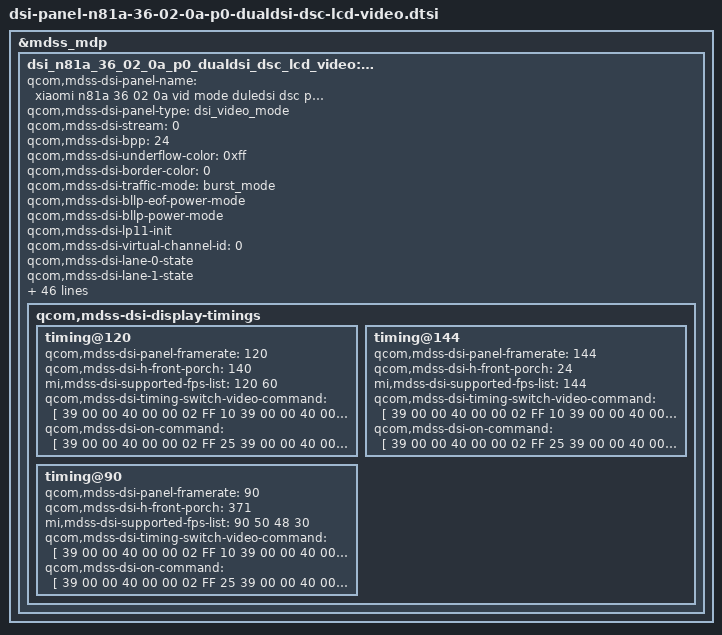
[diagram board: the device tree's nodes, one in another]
/* Copyright (c) 2015, The Linux Foundation. All rights reserved.
 *
 * This program is free software; you can redistribute it and/or modify
 * it under the terms of the GNU General Public License version 2 and
 * only version 2 as published by the Free Software Foundation.
 *
 * This program is distributed in the hope that it will be useful,
 * but WITHOUT ANY WARRANTY; without even the implied warranty of
 * MERCHANTABILITY or FITNESS FOR A PARTICULAR PURPOSE.  See the
 * GNU General Public License for more details.
 */

/*---------------------------------------------------------------------------
 * This file is autogenerated file using gcdb parser. Please do not edit it.
 * Update input XML file to add a new entry or update variable in this file
 * VERSION = "1.0"
 *---------------------------------------------------------------------------*/
&mdss_mdp {
    dsi_n81a_36_02_0a_p0_dualdsi_dsc_lcd_video: qcom,mdss_dsi_n81a_36_02_0a_p0_duledsi_dsc_vid {
        qcom,mdss-dsi-panel-name = "xiaomi n81a 36 02 0a vid mode duledsi dsc panel";
        qcom,mdss-dsi-panel-type = "dsi_video_mode";

        qcom,mdss-dsi-stream = <0>;
        qcom,mdss-dsi-bpp = <24>;
        qcom,mdss-dsi-underflow-color = <0xff>;
        qcom,mdss-dsi-border-color = <0>;
        qcom,mdss-dsi-traffic-mode = "burst_mode";
        qcom,mdss-dsi-bllp-eof-power-mode;
        qcom,mdss-dsi-bllp-power-mode;
        qcom,mdss-dsi-lp11-init;
        qcom,mdss-dsi-virtual-channel-id = <0>;
        qcom,mdss-dsi-lane-0-state;
        qcom,mdss-dsi-lane-1-state;
        qcom,mdss-dsi-lane-2-state;
        qcom,mdss-dsi-lane-3-state;
        qcom,mdss-dsi-dma-trigger = "trigger_sw";
        qcom,mdss-dsi-mdp-trigger = "none";
        qcom,mdss-dsi-reset-sequence = <0 10>, <1 3>, <0 3>, <1 15>;
        qcom,adjust-timer-wakeup-ms = <1>;
        qcom,mdss-pan-physical-width-dimension = <2632>;//could display area
        qcom,mdss-pan-physical-height-dimension = <1754>;
        mi,mdss-dsi-fac-bl-max-level = <2047>;
        mi,mdss-fac-brightness-max-level = <2047>;
        qcom,mdss-dsi-tx-eot-append;
        qcom,mdss-dsi-rx-eot-ignore;

        qcom,cmd-sync-wait-broadcast;
        qcom,mdss-dsi-panel-broadcast-mode;

        // qcom,esd-check-enabled;
        qcom,mdss-dsi-panel-status-check-mode ="irq_check";
        qcom,mdss-dsi-panel-status-command = [06 01 00 00 00 00 01 0A];
        qcom,mdss-dsi-panel-status-command-state = "dsi_lp_mode";
        qcom,mdss-dsi-panel-status-value = <0x9D>;
        qcom,mdss-dsi-panel-status-read-length = <1>;

        qcom,bl-update-flag = "delay_until_first_frame";
        qcom,mdss-dsi-phy-voltage = <0x51>;
        qcom,mdss-dsi-clk-strength = <0xFF>;
        qcom,mdss-dsi-panel-hdr-enabled;
        qcom,mdss-dsi-panel-hdr-color-primaries = <14500 15500 32000
            17000 15500 30000 8000 3000>;
        qcom,mdss-dsi-panel-peak-brightness = <4200000>;
        qcom,mdss-dsi-panel-blackness-level = <3230>;

        qcom,mdss-dsi-pan-enable-dynamic-fps;
        qcom,mdss-dsi-pan-fps-update = "dfps_immediate_porch_mode_vfp";
        qcom,dsi-supported-dfps-list = <120 144 90 60 50 48 30>;

        qcom,mdss-dsi-display-timings {
            timing@120{
                qcom,mdss-dsi-panel-framerate = <120>;
                qcom,mdss-dsi-h-front-porch = <140>;
                mi,mdss-dsi-supported-fps-list = <120 60>;
                qcom,mdss-dsi-timing-switch-video-command = [
                    39 00 00 40 00 00 02 FF 10
                    39 00 00 40 00 00 02 B2 91
                    39 00 00 00 00 00 02 B3 40
                ];
                qcom,mdss-dsi-on-command= [
                    //autoporch setting
                    39 00 00 40 00 00 02 FF 25
                    39 00 00 40 00 00 02 FB 01
                    39 00 00 00 00 00 02 05 00

                    //ESD init
                    39 00 00 40 00 00 02 FF 27
                    39 00 00 40 00 00 02 FB 01
                    39 00 00 40 00 00 02 D0 31
                    39 00 00 40 00 00 02 D1 20
                    39 00 00 40 00 00 02 D2 38
                    39 00 00 40 00 00 02 DE 43
                    39 00 00 00 00 00 02 DF 02

                    //CABC start
                    39 00 00 40 00 00 02 FF 23
                    39 00 00 40 00 00 02 FB 01
                    39 00 00 40 00 00 02 00 80
                    39 00 00 40 00 00 02 01 84
                    39 00 00 40 00 00 02 05 2D
                    39 00 00 40 00 00 02 06 00
                    39 00 00 40 00 00 02 11 03
                    39 00 00 40 00 00 02 12 C7
                    39 00 00 40 00 00 02 15 AE
                    39 00 00 40 00 00 02 16 16
                    //UI mode
                    39 00 00 40 00 00 02 29 0A
                    39 00 00 40 00 00 02 30 FF
                    39 00 00 40 00 00 02 31 FE
                    39 00 00 40 00 00 02 32 FD
                    39 00 00 40 00 00 02 33 FB
                    39 00 00 40 00 00 02 34 F8
                    39 00 00 40 00 00 02 35 F5
                    39 00 00 40 00 00 02 36 F3
                    39 00 00 40 00 00 02 37 F2
                    39 00 00 40 00 00 02 38 F2
                    39 00 00 40 00 00 02 39 F2
                    39 00 00 40 00 00 02 3A EF
                    39 00 00 40 00 00 02 3B EC
                    39 00 00 40 00 00 02 3D E9
                    39 00 00 40 00 00 02 3F E5
                    39 00 00 40 00 00 02 40 E5
                    39 00 00 40 00 00 02 41 E5
                    //STILL mode
                    39 00 00 40 00 00 02 2A 13
                    39 00 00 40 00 00 02 45 FF
                    39 00 00 40 00 00 02 46 F4
                    39 00 00 40 00 00 02 47 E7
                    39 00 00 40 00 00 02 48 DA
                    39 00 00 40 00 00 02 49 CD
                    39 00 00 40 00 00 02 4A C0
                    39 00 00 40 00 00 02 4B B3
                    39 00 00 40 00 00 02 4C B1
                    39 00 00 40 00 00 02 4D B1
                    39 00 00 40 00 00 02 4E B1
                    39 00 00 40 00 00 02 4F 95
                    39 00 00 40 00 00 02 50 79
                    39 00 00 40 00 00 02 51 5C
                    39 00 00 40 00 00 02 52 58
                    39 00 00 40 00 00 02 53 58
                    39 00 00 40 00 00 02 54 58
                    //MOVING mode
                    39 00 00 40 00 00 02 2B 0E
                    39 00 00 40 00 00 02 58 FF
                    39 00 00 40 00 00 02 59 FB
                    39 00 00 40 00 00 02 5A F7
                    39 00 00 40 00 00 02 5B F3
                    39 00 00 40 00 00 02 5C EF
                    39 00 00 40 00 00 02 5D E3
                    39 00 00 40 00 00 02 5E D8
                    39 00 00 40 00 00 02 5F D6
                    39 00 00 40 00 00 02 60 D6
                    39 00 00 40 00 00 02 61 D6
                    39 00 00 40 00 00 02 62 C8
                    39 00 00 40 00 00 02 63 B7
                    39 00 00 40 00 00 02 64 AA
                    39 00 00 40 00 00 02 65 A8
                    39 00 00 40 00 00 02 66 A8
                    39 00 00 00 00 00 02 67 A8
                    //CABC end

                    39 00 00 40 00 00 02 FF 10
                    39 00 00 40 00 00 02 FB 01
                    39 00 00 40 00 00 02 35 00
                    39 00 00 40 00 00 07 3B 03 8C 1A 04 04 00
                    39 00 00 40 00 00 03 51 0F FF
                    39 00 00 40 00 00 02 53 24
                    39 00 00 40 00 00 02 90 03
                    39 00 00 40 00 00 11 91 89 28 00 10 D2 00 02 9D 01 B1 00 0A 06 EF 04 82
                    39 00 00 40 00 00 03 92 10 F0
                    39 00 00 40 00 00 02 9D 01
                    39 00 00 40 00 00 02 B2 91
                    39 00 00 00 00 00 02 B3 40
                    39 00 00 00 78 00 01 11
                    39 00 00 00 00 00 01 29
                ];
                #include "dsi-panel-n81a-36-02-0a-dualdsi-dsc-lcd-video-qcomcommon.dtsi"
            };
            timing@144{
                qcom,mdss-dsi-panel-framerate = <144>;
                qcom,mdss-dsi-h-front-porch = <24>;
                mi,mdss-dsi-supported-fps-list = <144>;
                qcom,mdss-dsi-timing-switch-video-command = [
                    39 00 00 40 00 00 02 FF 10
                    39 00 00 40 00 00 02 B2 00
                    39 00 00 00 00 00 02 B3 00
                ];
                qcom,mdss-dsi-on-command= [
                    //autoporch setting
                    39 00 00 40 00 00 02 FF 25
                    39 00 00 40 00 00 02 FB 01
                    39 00 00 00 00 00 02 05 00

                    //ESD init
                    39 00 00 40 00 00 02 FF 27
                    39 00 00 40 00 00 02 FB 01
                    39 00 00 40 00 00 02 D0 31
                    39 00 00 40 00 00 02 D1 20
                    39 00 00 40 00 00 02 D2 38
                    39 00 00 40 00 00 02 DE 43
                    39 00 00 00 00 00 02 DF 02

                    //CABC start
                    39 00 00 40 00 00 02 FF 23
                    39 00 00 40 00 00 02 FB 01
                    39 00 00 40 00 00 02 00 80
                    39 00 00 40 00 00 02 01 84
                    39 00 00 40 00 00 02 05 2D
                    39 00 00 40 00 00 02 06 00
                    39 00 00 40 00 00 02 11 03
                    39 00 00 40 00 00 02 12 C7
                    39 00 00 40 00 00 02 15 AE
                    39 00 00 40 00 00 02 16 16
                    //UI mode
                    39 00 00 40 00 00 02 29 0A
                    39 00 00 40 00 00 02 30 FF
                    39 00 00 40 00 00 02 31 FE
                    39 00 00 40 00 00 02 32 FD
                    39 00 00 40 00 00 02 33 FB
                    39 00 00 40 00 00 02 34 F8
                    39 00 00 40 00 00 02 35 F5
                    39 00 00 40 00 00 02 36 F3
                    39 00 00 40 00 00 02 37 F2
                    39 00 00 40 00 00 02 38 F2
                    39 00 00 40 00 00 02 39 F2
                    39 00 00 40 00 00 02 3A EF
                    39 00 00 40 00 00 02 3B EC
                    39 00 00 40 00 00 02 3D E9
                    39 00 00 40 00 00 02 3F E5
                    39 00 00 40 00 00 02 40 E5
                    39 00 00 40 00 00 02 41 E5
                    //STILL mode
                    39 00 00 40 00 00 02 2A 13
                    39 00 00 40 00 00 02 45 FF
                    39 00 00 40 00 00 02 46 F4
                    39 00 00 40 00 00 02 47 E7
                    39 00 00 40 00 00 02 48 DA
                    39 00 00 40 00 00 02 49 CD
                    39 00 00 40 00 00 02 4A C0
                    39 00 00 40 00 00 02 4B B3
                    39 00 00 40 00 00 02 4C B1
                    39 00 00 40 00 00 02 4D B1
                    39 00 00 40 00 00 02 4E B1
                    39 00 00 40 00 00 02 4F 95
                    39 00 00 40 00 00 02 50 79
                    39 00 00 40 00 00 02 51 5C
                    39 00 00 40 00 00 02 52 58
                    39 00 00 40 00 00 02 53 58
                    39 00 00 40 00 00 02 54 58
                    //MOVING mode
                    39 00 00 40 00 00 02 2B 0E
                    39 00 00 40 00 00 02 58 FF
                    39 00 00 40 00 00 02 59 FB
                    39 00 00 40 00 00 02 5A F7
                    39 00 00 40 00 00 02 5B F3
                    39 00 00 40 00 00 02 5C EF
                    39 00 00 40 00 00 02 5D E3
                    39 00 00 40 00 00 02 5E D8
                    39 00 00 40 00 00 02 5F D6
                    39 00 00 40 00 00 02 60 D6
                    39 00 00 40 00 00 02 61 D6
                    39 00 00 40 00 00 02 62 C8
                    39 00 00 40 00 00 02 63 B7
                    39 00 00 40 00 00 02 64 AA
                    39 00 00 40 00 00 02 65 A8
                    39 00 00 40 00 00 02 66 A8
                    39 00 00 00 00 00 02 67 A8
                    //CABC end

                    39 00 00 40 00 00 02 FF 10
                    39 00 00 40 00 00 02 FB 01
                    39 00 00 40 00 00 02 35 00
                    39 00 00 40 00 00 07 3B 03 8C 1A 04 04 00
                    39 00 00 40 00 00 03 51 0F FF
                    39 00 00 40 00 00 02 53 24
                    39 00 00 40 00 00 02 90 03
                    39 00 00 40 00 00 11 91 89 28 00 10 D2 00 02 9D 01 B1 00 0A 06 EF 04 82
                    39 00 00 40 00 00 03 92 10 F0
                    39 00 00 40 00 00 02 9D 01
                    39 00 00 40 00 00 02 B2 00
                    39 00 00 00 00 00 02 B3 00
                    39 00 00 00 78 00 01 11
                    39 00 00 00 00 00 01 29
                ];
                #include "dsi-panel-n81a-36-02-0a-dualdsi-dsc-lcd-video-qcomcommon.dtsi"
            };
            timing@90{
                qcom,mdss-dsi-panel-framerate = <90>;
                qcom,mdss-dsi-h-front-porch = <371>;
                mi,mdss-dsi-supported-fps-list = <90 50 48 30>;
                qcom,mdss-dsi-timing-switch-video-command = [
                    39 00 00 40 00 00 02 FF 10
                    39 00 00 40 00 00 02 B2 00
                    39 00 00 00 00 00 02 B3 80
                ];
                qcom,mdss-dsi-on-command= [
                    //autoporch setting
                    39 00 00 40 00 00 02 FF 25
                    39 00 00 40 00 00 02 FB 01
                    39 00 00 00 00 00 02 05 00

                    //ESD init
                    39 00 00 40 00 00 02 FF 27
                    39 00 00 40 00 00 02 FB 01
                    39 00 00 40 00 00 02 D0 31
                    39 00 00 40 00 00 02 D1 20
                    39 00 00 40 00 00 02 D2 38
                    39 00 00 40 00 00 02 DE 43
                    39 00 00 00 00 00 02 DF 02

                    //CABC start
                    39 00 00 40 00 00 02 FF 23
                    39 00 00 40 00 00 02 FB 01
                    39 00 00 40 00 00 02 00 80
                    39 00 00 40 00 00 02 01 84
                    39 00 00 40 00 00 02 05 2D
                    39 00 00 40 00 00 02 06 00
                    39 00 00 40 00 00 02 11 03
                    39 00 00 40 00 00 02 12 C7
                    39 00 00 40 00 00 02 15 AE
                    39 00 00 40 00 00 02 16 16
                    //UI mode
                    39 00 00 40 00 00 02 29 0A
                    39 00 00 40 00 00 02 30 FF
                    39 00 00 40 00 00 02 31 FE
                    39 00 00 40 00 00 02 32 FD
                    39 00 00 40 00 00 02 33 FB
                    39 00 00 40 00 00 02 34 F8
                    39 00 00 40 00 00 02 35 F5
                    39 00 00 40 00 00 02 36 F3
                    39 00 00 40 00 00 02 37 F2
                    39 00 00 40 00 00 02 38 F2
                    39 00 00 40 00 00 02 39 F2
                    39 00 00 40 00 00 02 3A EF
                    39 00 00 40 00 00 02 3B EC
                    39 00 00 40 00 00 02 3D E9
                    39 00 00 40 00 00 02 3F E5
                    39 00 00 40 00 00 02 40 E5
                    39 00 00 40 00 00 02 41 E5
                    //STILL mode
                    39 00 00 40 00 00 02 2A 13
                    39 00 00 40 00 00 02 45 FF
                    39 00 00 40 00 00 02 46 F4
                    39 00 00 40 00 00 02 47 E7
                    39 00 00 40 00 00 02 48 DA
                    39 00 00 40 00 00 02 49 CD
                    39 00 00 40 00 00 02 4A C0
                    39 00 00 40 00 00 02 4B B3
                    39 00 00 40 00 00 02 4C B1
                    39 00 00 40 00 00 02 4D B1
                    39 00 00 40 00 00 02 4E B1
                    39 00 00 40 00 00 02 4F 95
                    39 00 00 40 00 00 02 50 79
                    39 00 00 40 00 00 02 51 5C
                    39 00 00 40 00 00 02 52 58
                    39 00 00 40 00 00 02 53 58
                    39 00 00 40 00 00 02 54 58
                    //MOVING mode
                    39 00 00 40 00 00 02 2B 0E
                    39 00 00 40 00 00 02 58 FF
                    39 00 00 40 00 00 02 59 FB
                    39 00 00 40 00 00 02 5A F7
                    39 00 00 40 00 00 02 5B F3
                    39 00 00 40 00 00 02 5C EF
                    39 00 00 40 00 00 02 5D E3
                    39 00 00 40 00 00 02 5E D8
                    39 00 00 40 00 00 02 5F D6
                    39 00 00 40 00 00 02 60 D6
                    39 00 00 40 00 00 02 61 D6
                    39 00 00 40 00 00 02 62 C8
                    39 00 00 40 00 00 02 63 B7
                    39 00 00 40 00 00 02 64 AA
                    39 00 00 40 00 00 02 65 A8
                    39 00 00 40 00 00 02 66 A8
                    39 00 00 00 00 00 02 67 A8
                    //CABC end

                    39 00 00 40 00 00 02 FF 10
                    39 00 00 40 00 00 02 FB 01
                    39 00 00 40 00 00 02 35 00
                    39 00 00 40 00 00 07 3B 03 8C 1A 04 04 00
                    39 00 00 40 00 00 03 51 0F FF
                    39 00 00 40 00 00 02 53 24
                    39 00 00 40 00 00 02 90 03
                    39 00 00 40 00 00 11 91 89 28 00 10 D2 00 02 9D 01 B1 00 0A 06 EF 04 82
                    39 00 00 40 00 00 03 92 10 F0
                    39 00 00 40 00 00 02 9D 01
                    39 00 00 40 00 00 02 B2 00
                    39 00 00 00 00 00 02 B3 80
                    39 00 00 00 78 00 01 11
                    39 00 00 00 00 00 01 29
                ];
                #include "dsi-panel-n81a-36-02-0a-dualdsi-dsc-lcd-video-qcomcommon.dtsi"
            };
        };
    };
};

&dsi_n81a_36_02_0a_p0_dualdsi_dsc_lcd_video {
    mi,panel-id = <0x4E383161 0x50360200>;
    mi,feature-enabled;
    mi,is-tddi-flag;
    mi,mdss-panel-on-dimming-delay = <300>;
    mi,esd-err-irq-gpio = <&tlmm 87 0x2004>; /* trig-flags: falling-0x0002 rasing-0x0001*/
    mi,esd-err-irq-gpio-second = <&tlmm 137 0x2004>; /* trig-flags: falling-0x0002 rasing-0x0001*/
    mi,mdss-dsi-panel-xy-coordinate = <0x6 0x18>;
    mi,mdss-dsi-panel-max-luminance = <0x6 0x4>;
    mi,thermal-dimming-flag;
    mi,video-mode-multi-timing;

    qcom,mdss-dsi-display-timings {
        timing@120{
        #include "dsi-panel-n81a-36-02-0a-dualdsi-dsc-lcd-video-micommon.dtsi"
        };
        timing@144{
        #include "dsi-panel-n81a-36-02-0a-dualdsi-dsc-lcd-video-micommon.dtsi"
        };
        timing@90{
        #include "dsi-panel-n81a-36-02-0a-dualdsi-dsc-lcd-video-micommon.dtsi"
        };
    };
};
